# SPGSS2_1.0 register map
Vendor: Texas Instruments
Registers are 32-bit, read-write, no defined reset value unless marked. A register's access mark holds for its fields unless they carry their own. Offsets are as the file gives them; [hi:lo] are bit positions; lines under a group give offsets from that group; {n}, {i} and the like mark numbered series; 'fields as' and 'values as' point back to an identical list; <NAME> marks a mode.

## SPGSS2 (part 3 of 4)
0x27020 SPGSS2_UC3_I2CC_IPSTANDARD_CPU_INT group
  0x00 SPGSS2_UC3_I2CC_IPSTANDARD_IIDX ro — Interrupt index
    [7:0] STAT — I2C Module Interrupt Vector Value. This register provides the highes priority interrupt index. A read clears the corresponding interrupt flag in RIS and MISC. 15h-1Fh = Reserved
      0=NO_INTR (No interrupt pending); 1=RXDONEFG (Data received); 2=TXDONEFG (data transmitted); 3=RXTRG (Receive Trigger); 4=TXTRG (Transmit Trigger); 5=RXFULL (RX FIFO FULL Event/interrupt pending); 6=TXEMPTY (Transmit FIFO/Buffer Empty Event/interrupt pending); 8=NACKFG (Address/Data NACK); 9=STARTFG (Start Event); 10=STOPFG (Stop Event); 11=ARBLOSTFG (Arbitration Lost); 12=PEC_RX_ERR (PEC Receive Error Event); 13=TIMEOUTA (Timeout A Event); 14=TIMEOUTB (Timeout B Event); 16=DMA_DONE_RX (DMA DONE on Channel RX); 17=DMA_DONE_TX (DMA DONE on Channel TX); 19=DMA_PREIRQ_RX (DMA PRE IRQ INTERRUPT); 20=DMA_PREIRQ_TX (DMA PRE IRQ INTERRUPT)
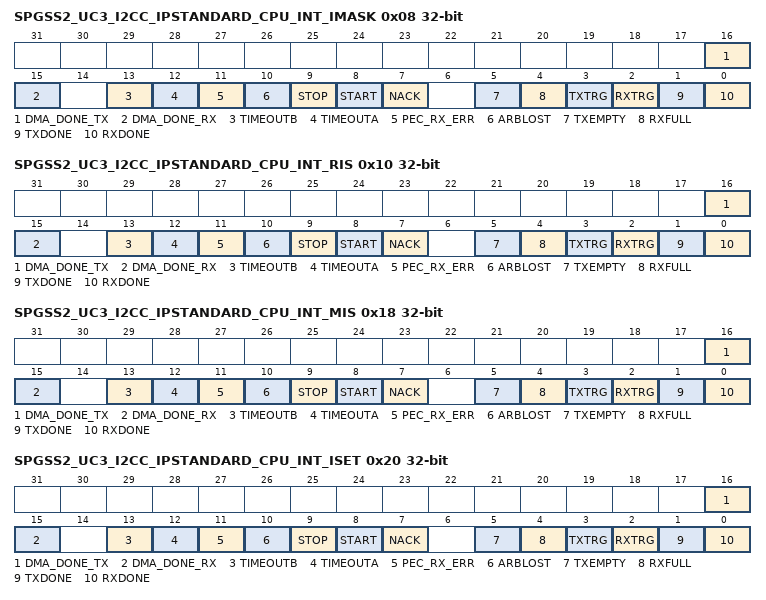
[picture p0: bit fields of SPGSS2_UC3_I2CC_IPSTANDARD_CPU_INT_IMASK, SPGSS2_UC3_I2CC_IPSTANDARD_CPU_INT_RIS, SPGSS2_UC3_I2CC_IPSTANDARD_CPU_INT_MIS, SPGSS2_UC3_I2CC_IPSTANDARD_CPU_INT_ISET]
  0x08 SPGSS2_UC3_I2CC_IPSTANDARD_CPU_INT_IMASK — Interrupt mask
    [16] DMA_DONE_TX — DMA Done on Event Channel TX
      0=CLR (Interrupt disabled); 1=SET (Set Interrupt Mask)
    [15] DMA_DONE_RX — DMA Done on Event Channel RX
      0=CLR (Interrupt disabled); 1=SET (Set Interrupt Mask)
    [13] TIMEOUTB — Timeout B Interrupt
      0=CLR (Clear Interrupt Mask); 1=SET (Set Interrupt Mask)
    [12] TIMEOUTA — TIMEOUTA interrupt
      0=CLR (Clear Interrupt Mask); 1=SET (Set Interrupt Mask)
    [11] PEC_RX_ERR — RX Pec Error Interrupt
      0=CLR (Clear Interrupt Mask); 1=SET (Set Interrupt Mask)
    [10] ARBLOST — Arbitration Lost interrupt
      0=CLR (Clear Interrupt Mask); 1=SET (Set Interrupt Mask)
    [9] STOP — STOP interrupt
      0=CLR (Clear Interrupt Mask); 1=SET (Set Interrupt Mask)
    [8] START — START interrupt
      0=CLR (Clear Interrupt Mask); 1=SET (Set Interrupt Mask)
    [7] NACK — NACK interrupt
      0=CLR (Clear Interrupt Mask); 1=SET (Set Interrupt Mask)
    [5] TXEMPTY — Transmit FIFO/Buffer Empty interrupt.
      0=CLR (Clear Interrupt Mask); 1=SET (Set Interrupt Mask)
    [4] RXFULL — RXFIFO full event
      0=CLR (Clear Interrupt Mask); 1=SET (Set Interrupt Mask)
    [3] TXTRG — Transmit Trigger
      0=CLR (Clear Interrupt Mask); 1=SET (Set Interrupt Mask)
    [2] RXTRG — Receive Trigger
      0=CLR (Clear Interrupt Mask); 1=SET (Set Interrupt Mask)
    [1] TXDONE — Transmit Transaction completed Interrupt
      0=CLR (Clear Interrupt Mask); 1=SET (Set Interrupt Mask)
    [0] RXDONE — RXDONE interrupt
      0=CLR (Clear Interrupt Mask); 1=SET (Set Interrupt Mask)
  0x10 SPGSS2_UC3_I2CC_IPSTANDARD_CPU_INT_RIS — Raw interrupt status
    [16] DMA_DONE_TX — DMA Done on Event Channel TX
      0=CLR (Interrupt disabled); 1=SET (Set Interrupt Mask)
    [15] DMA_DONE_RX — DMA Done on Event Channel RX
      0=CLR (Interrupt disabled); 1=SET (Set Interrupt Mask)
    [13] TIMEOUTB — Timeout B Interrupt
      0=CLR (Interrupt did not occur); 1=SET (Interrupt occured)
    [12] TIMEOUTA — Timeout A Interrupt
      0=CLR (Interrupt did not occur); 1=SET (Set Interrupt Mask)
    [11] PEC_RX_ERR — Receive PEC Error Interrupt: set when the calculated PEC does not match received PEC
      0=CLR (Interrupt did not occur); 1=SET (Interrupt Occured)
    [10] ARBLOST — Arbitration Lost Interrupt: in multi-controller systems, when this controller loses out during arbitration
      0=CLR (Interrupt did not occur); 1=SET (Set Interrupt Mask)
    [9] STOP — STOP Detection Interrupt
      0=CLR (Interrupt did not occur); 1=SET (Set Interrupt Mask)
    [8] START — START Detection Interrupt
      0=CLR (Interrupt did not occur); 1=SET (Set Interrupt Mask)
    [7] NACK — Address/Data NACK Interrupt: set when address or data nack is received
      0=CLR (Interrupt did not occur); 1=SET (Set Interrupt Mask)
    [5] TXEMPTY — Transmit FIFO Empty: set when Transmit FIFO is empty
      0=CLR (Interrupt did not occur); 1=SET (Interrupt occured)
    [4] RXFULL — RXFIFO full event. This interrupt is set when receive FIFO is full.
      0=CLR (Interrupt did not occur); 1=SET (Interrupt occured)
    [3] TXTRG — Transmit Trigger When FIFO is present, as per IFLS settings When FIFO is not present, trigger when transmit buffer is empty
      0=CLR (Clear Interrupt Mask); 1=SET (Set Interrupt Mask)
    [2] RXTRG — Receive Trigger When FIFO is present, as per IFLS settings when FIFO is not present, this indicates when buffer is full
      0=CLR (Clear Interrupt Mask); 1=SET (Set Interrupt Mask)
    [1] TXDONE — Transmit Done Interrupt: TXDONE interrupt is raised when a burst length completes Or, in case of quick command, when a quick command with R/Wn bit set to '0'
      0=CLR (Interrupt did not occur); 1=SET (Set Interrupt Mask)
    [0] RXDONE — Receive Done Interrupt: RXDONE interrupt is raised when a burst length completes Or, in case of quick command, when a quick command with R/Wn bit set to '1'
      0=CLR (Interrupt did not occur); 1=SET (Set Interrupt Mask)
  0x18 SPGSS2_UC3_I2CC_IPSTANDARD_CPU_INT_MIS — Masked interrupt status
    [16] DMA_DONE_TX — DMA Done on Event Channel TX
      0=CLR (Interrupt disabled); 1=SET (Set Interrupt Mask)
    [15] DMA_DONE_RX — DMA Done on Event Channel RX
      0=CLR (Interrupt disabled); 1=SET (Set Interrupt Mask)
    [13] TIMEOUTB — Timeout B Interrupt
      0=CLR (Clear interrupt mask); 1=SET (Set interrupt mask)
    [12] TIMEOUTA — Timeout A Interrupt
      0=CLR (Interrupt did not occur); 1=SET (Set Interrupt Mask)
    [11] PEC_RX_ERR — RX Pec Error Interrupt
      0=CLR (Clear interrupt mask); 1=SET (Set interrupt mask)
    [10] ARBLOST — Arbitration Lost Interrupt
      0=CLR (Interrupt did not occur); 1=SET (Set Interrupt Mask)
    [9] STOP — STOP Detection Interrupt
      0=CLR (Interrupt did not occur); 1=SET (Set Interrupt Mask)
    [8] START — START Detection Interrupt
      0=CLR (Interrupt did not occur); 1=SET (Set Interrupt Mask)
    [7] NACK — Address/Data NACK Interrupt
      0=CLR (Interrupt did not occur); 1=SET (Set Interrupt Mask)
    [5] TXEMPTY — Transmit FIFO Empty masked interrupt. This interrupt is set if all data in the Transmit FIFO have been shifted out and the transmit goes into idle mode.
      0=CLR (Interrupt did not occur); 1=SET (Interrupt occured)
    [4] RXFULL — Masked RXFIFO full event
      0=CLR (Interrupt did not occur); 1=SET (Interrupt occured)
    [3] TXTRG — Transmit Trigger
      0=CLR (Clear Interrupt Mask); 1=SET (Set Interrupt Mask)
    [2] RXTRG — Receive Trigger
      0=CLR (Clear Interrupt Mask); 1=SET (Set Interrupt Mask)
    [1] TXDONE — Transmit Transaction completed Interrupt
      0=CLR (Interrupt did not occur); 1=SET (Set Interrupt Mask)
    [0] RXDONE — Receive Data Interrupt
      0=CLR (Interrupt did not occur); 1=SET (Set Interrupt Mask)
  0x20 SPGSS2_UC3_I2CC_IPSTANDARD_CPU_INT_ISET — Interrupt set
    [16] DMA_DONE_TX — DMA Done on Event Channel TX
      0=NO_EFFECT (Interrupt disabled); 1=SET (Set Interrupt Mask)
    [15] DMA_DONE_RX — DMA Done on Event Channel RX
      0=NO_EFFECT (Interrupt disabled); 1=SET (Set Interrupt Mask)
    [13] TIMEOUTB — Timeout B Interrupt
      0=NO_EFFECT (Writing 0 has no effect); 1=SET (Set interrupt)
    [12] TIMEOUTA — Timeout A interrupt
      0=NO_EFFECT (Writing 0 has no effect); 1=SET (Set Interrupt Mask)
    [11] PEC_RX_ERR — RX Pec Error Interrupt
      0=NO_EFFECT (Writing 0 has no effect); 1=SET (Set interrupt)
    [10] ARBLOST — Arbitration Lost Interrupt
      values as TIMEOUTA
    [9] STOP — STOP Detection Interrupt
      values as TIMEOUTA
    [8] START — START Detection Interrupt
      values as TIMEOUTA
    [7] NACK — Address/Data NACK Interrupt
      values as TIMEOUTA
    [5] TXEMPTY — Transmit FIFO Empty interrupt mask. This interrupt is set if all data in the Transmit FIFO have been shifted out and the transmit goes into idle mode.
      0=NO_EFFECT (Writing 0 has no effect); 1=SET (Set Interrupt)
    [4] RXFULL — RXFIFO full event.
      0=NO_EFFECT (Writing 0 has no effect); 1=SET (Set Interrupt)
    [3] TXTRG — Transmit Trigger
      0=NO_EFFECT (Clear Interrupt Mask); 1=SET (Set Interrupt Mask)
    [2] RXTRG — Receive Trigger
      values as TXTRG
    [1] TXDONE — Transmit Transaction completed Interrupt
      values as TIMEOUTA
    [0] RXDONE — Receive Data Interrupt Signals that a byte has been received
      values as TIMEOUTA
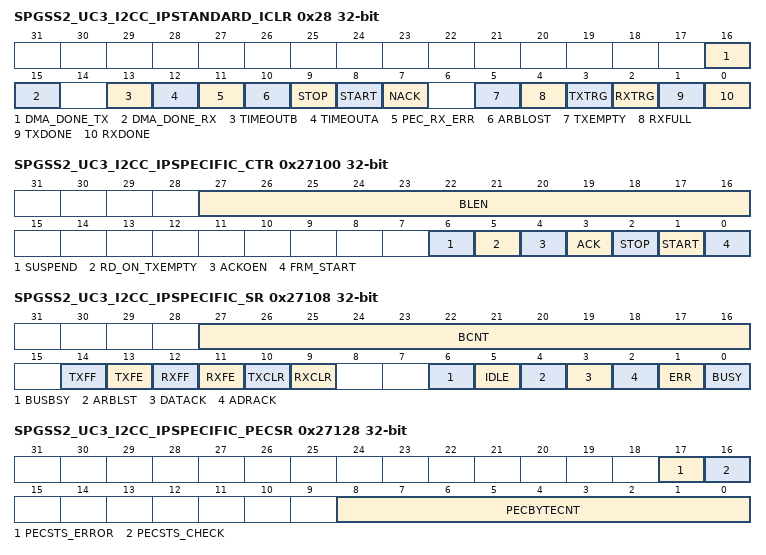
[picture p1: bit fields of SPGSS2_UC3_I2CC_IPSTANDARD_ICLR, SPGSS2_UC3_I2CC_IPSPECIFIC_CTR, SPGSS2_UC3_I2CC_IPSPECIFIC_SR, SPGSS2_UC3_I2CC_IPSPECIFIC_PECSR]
  0x28 SPGSS2_UC3_I2CC_IPSTANDARD_ICLR — Interrupt clear
    [16] DMA_DONE_TX — DMA Done on Event Channel TX
      0=NO_EFFECT (Interrupt disabled); 1=CLR (Set Interrupt Mask)
    [15] DMA_DONE_RX — DMA Done on Event Channel RX
      0=NO_EFFECT (Interrupt disabled); 1=CLR (Set Interrupt Mask)
    [13] TIMEOUTB — Timeout B Interrupt
      0=NO_EFFECT (Writing 0 has no effect); 1=CLR (Clear Interrupt)
    [12] TIMEOUTA — Timeout A interrupt
      0=NO_EFFECT (Writing 0 has no effect); 1=CLR (Set Interrupt Mask)
    [11] PEC_RX_ERR — RX Pec Error Interrupt
      values as TIMEOUTB
    [10] ARBLOST — Arbitration Lost Interrupt
      values as TIMEOUTA
    [9] STOP — STOP Detection Interrupt
      values as TIMEOUTA
    [8] START — START Detection Interrupt
      values as TIMEOUTA
    [7] NACK — Address/Data NACK Interrupt
      values as TIMEOUTA
    [5] TXEMPTY — Transmit FIFO Empty interrupt mask. This interrupt is set if all data in the Transmit FIFO have been shifted out and the transmit goes into idle mode.
      values as TIMEOUTB
    [4] RXFULL — RXFIFO full event.
      values as TIMEOUTB
    [3] TXTRG — Transmit FIFO Trigger
      0=NO_EFFECT (Clear Interrupt Mask); 1=CLR (Set Interrupt Mask)
    [2] RXTRG — Receive Trigger
      values as TXTRG
    [1] TXDONE — Transmit Transaction completed Interrupt
      values as TIMEOUTA
    [0] RXDONE — Receive Data Interrupt Signals that a byte has been received
      values as TIMEOUTA
0x27100 SPGSS2_UC3_I2CC_IPSPECIFIC_CTR — Control Register
  [27:16] BLEN — I2C transaction length This field contains the programmed length of bytes of the Transaction.
    0=MINIMUM (Smallest value); 0xFFF=MAXIMUM (Highest possible value)
  [6] SUSPEND — Suspend external communication
    0=DISABLE (Functional mode resumed); 1=ENABLE (External communication suspended)
  [5] RD_ON_TXEMPTY — Read on TX Empty
    0=DISABLE (No special behavior); 1=ENABLE (When 1 the Controller will transmit all bytes from the TX FIFO before continuing with the programmed Burst Run Read. If the DIR is not set to Read in the MSA then this bit is ignored. The Start must be set in the MCTR for proper I2C protocol. The Controller will first send the Start Condition, I2C Address with R/W bit set to write, before sending the bytes in the TX FIFO. When the TX FIFO is empty, the I2C transaction will continue as programmed in MTCR and MSA without sending a Stop Condition. This is intended to be used to perform simple I2C command based reads transition that will complete after initiating them without having to get an interrupt to turn the bus around.)
  [4] ACKOEN — ACK overrride Enable
    0=DISABLE (No special behavior); 1=ENABLE (When 1 and the Controller is receiving data and the number of bytes indicated in MBLEN have been received, the state machine will generate an rxdone interrupt and wait at the start of the ACK for FW to indicate if an ACK or NACK should be sent. The ACK or NACK is selected by writing the MCTR register and setting ACK accordingly. The other fields in this register can also be written at this time to continue on with the transaction. If a NACK is sent the state machine will automatically send a Stop.)
  [3] ACK — Data Acknowledge Enable. Software needs to configure this bit to send the ACK or NACK. See field decoding in Table: MCTR Field decoding.
    0=DISABLE (The last received data byte of a transaction is not acknowledged automatically .); 1=ENABLE (The last received data byte of a transaction is acknowledged automatically .)
  [2] STOP — Generate STOP
    0=DISABLE (The controller does not generate the STOP condition.); 1=ENABLE (The controller generates the STOP condition. See field decoding in Table: MCTR Field decoding.)
  [1] START — Generate START
    0=DISABLE (The controller does not generate the START condition.); 1=ENABLE (The controller generates the START or repeated START condition. See field decoding in Table: MCTR Field decoding.)
  [0] FRM_START — Start Transfer
    0=DISABLE (In standard mode, this encoding means the Controller is unable to transmit or receive data.); 1=ENABLE (The Controller is able to transmit or receive data. See field decoding in Table: MCTR Field decoding.)
0x27108 SPGSS2_UC3_I2CC_IPSPECIFIC_SR ro — Status Register
  [27:16] BCNT — Transaction Count This field contains the current count-down value of the transaction.
    values as SPGSS2_UC3_I2CC_IPSPECIFIC_CTR.BLEN
  [14] TXFF — Transmit FIFO Full The meaning of this bit depends on the state of the FEN bit in the CTL0 register.
    0=CLEARED (The transmitter is not full.); 1=SET (If the FIFO is disabled (FEN is 0), the transmit holding register is full. If the FIFO is enabled (FEN is 1), the transmit FIFO is full.)
  [13] TXFE — Transmit FIFO Empty The meaning of this bit depends on the state of the FEN bit in the CTL0 register.
    0=CLEARED (The transmitter has data to transmit.); 1=SET (If the FIFO is disabled (FEN is 0), the transmit holding register is empty. If the FIFO is enabled (FEN is 1), the transmit FIFO is empty.)
  [12] RXFF — Receive FIFO Full The meaning of this bit depends on the state of the FEN bit in the CTL0 register.
    0=CLEARED (The receiver can receive data.); 1=SET (If the FIFO is disabled (FEN is 0), the receive holding register is full. If the FIFO is enabled (FEN is 1), the receive FIFO is full.)
  [11] RXFE — Receive FIFO Empty The meaning of this bit depends on the state of the FEN bit in the CTL0 register.
    0=CLEARED (The receiver is not empty.); 1=SET (If the FIFO is disabled (FEN is 0), the receive holding register is empty. If the FIFO is enabled (FEN is 1), the receive FIFO is empty.)
  [10] TXCLR — TX FIFO Clear Status
    0=CLEARED (FIFO is not cleared); 1=SET (FIFO clear is complete)
  [9] RXCLR — RX FIFO Clear Status
    values as TXCLR
  [6] BUSBSY — I2C Bus is Busy Controller State Machine will wait until this bit to be cleared before starting a transaction. When first enabling the Controller in multi Controller environments, FW should wait for one I2C clock period after setting ACTIVE high before writing to the CTR register to start the transaction so that if SCL goes low it will trigger the BUSBSY.
    0=CLEARED (The I2C bus is idle.); 1=SET ('This Status bit is set on a START or when SCL goes low. It is cleared on a STOP, or when a SCL high bus busy timeout occurs and SCL and SDA are both high. This status is cleared when the ACTIVE bit is low. Note that the Controller State Machine will wait until this bit is cleared before starting an I2C transaction. When first enabling the Controller in multi Controller environments, FW should wait for one I2C clock period after setting ACTIVE high before writing to the MTCR register to start the transaction so that if SCL goes low it will trigger the BUSBSY.)
  [5] IDLE — I2C Idle
    0=CLEARED (The I2C controller is not idle.); 1=SET (The I2C controller is idle.)
  [4] ARBLST — Arbitration Lost
    0=CLEARED (The I2C controller won arbitration.); 1=SET (The I2C controller lost arbitration.)
  [3] DATACK — Acknowledge Data
    0=CLEARED (The transmitted data was acknowledged); 1=SET (The transmitted data was not acknowledged.)
  [2] ADRACK — Acknowledge Address
    0=CLEARED (The transmitted address was acknowledged); 1=SET (The transmitted address was not acknowledged.)
  [1] ERR — Error The error can be from the Target address not being acknowledged or the transmit data not being acknowledged.
    0=CLEARED (No error was detected on the last operation.); 1=SET (An error occurred on the last operation.)
  [0] BUSY — FSM Busy The BUSY bit is set during an ongoing transaction, so is set during the transmit/receive of the amount of data set in MBLEN including START, RESTART, Address and STOP signal generation when required for the current transaction.
    0=CLEARED (The controller is idle.); 1=SET (The controller is busy.)
0x27118 SPGSS2_UC3_I2CC_IPSPECIFIC_GFCTL — I2C Glitch Filter Control
  [8] AGFEN — Analog Glitch Suppression Enable
    0=DISABLE (Analog Glitch Filter disable); 1=ENABLE (Analog Glitch Filter enable)
0x27128 SPGSS2_UC3_I2CC_IPSPECIFIC_PECSR — PEC status register
  [17] PECSTS_ERROR — This status bit indicates if a PEC check error occurred in the transaction that occurred before the last Stop. Latched on Stop.
    0=CLEARED (Indicates PEC check error did not occurr in the transaction that occurred before the last Stop); 1=SET (Indicates if a PEC check error occurred in the transaction that occurred before the last Stop)
  [16] PECSTS_CHECK — This status bit indicates if the PEC was checked in the transaction that occurred before the last Stop. Latched on Stop.
    0=CLEARED (Indicates PEC was not checked in the transaction that occurred before the last Stop); 1=SET (Indicates if the PEC was checked in the transaction that occurred before the last Stop)
  [8:0] PECBYTECNT — PEC Byte Count This is the current PEC Byte Count of the Controller State Machine.
    0=MINIMUM (Minimum Value); 0x1FF=MAXIMUM (Maximum Value)
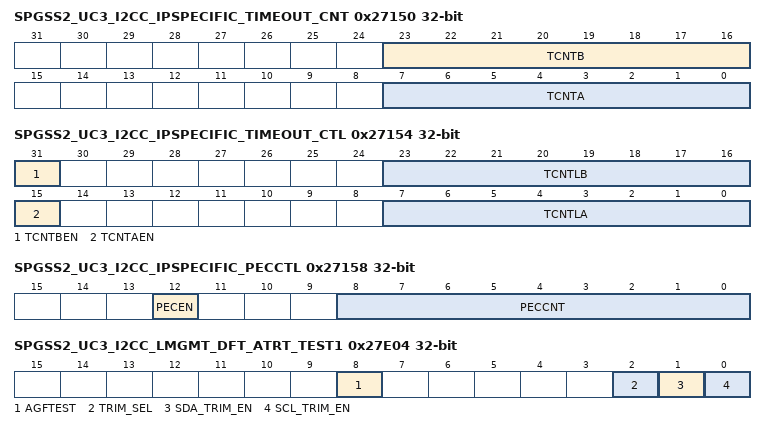
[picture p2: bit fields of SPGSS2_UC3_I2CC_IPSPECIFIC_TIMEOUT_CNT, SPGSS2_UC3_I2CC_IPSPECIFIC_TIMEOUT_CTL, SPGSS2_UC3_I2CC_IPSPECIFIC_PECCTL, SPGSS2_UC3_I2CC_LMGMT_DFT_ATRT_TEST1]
0x27150 SPGSS2_UC3_I2CC_IPSPECIFIC_TIMEOUT_CNT access per field — I2C Timeout Count Register
  [23:16] TCNTB rw — Timeout Count B Current Count: This field contains the upper 8 bits of a 12-bit current counter for timeout counter B
    0=MINIMUM (Smallest Value); 255=MAXIMUM (Highest possible value)
  [7:0] TCNTA ro — Timeout Count A Current Count: This field contains the upper 8 bits of a 12-bit current counter for timeout counter A
    values as TCNTB
0x27154 SPGSS2_UC3_I2CC_IPSPECIFIC_TIMEOUT_CTL — I2C Timeout Count Control Register
  [31] TCNTBEN — Timeout Counter B Enable
    0=DISABLE (Disable Timeout Counter B); 1=ENABLE (Enable Timeout Counter B)
  [23:16] TCNTLB — Timeout Count B Load: Counter B is used for SCL High Detection. This field contains the upper 8 bits of a 12-bit pre-load value for the Timeout B count. NOTE: The value of CNTLB must be greater than 1h. Each count is equal to 1* clock period. For example, with 10MHz functional clock one timeout period will be equal to1*100ns.
    0=MINIMUM (Smallest possible value); 255=MAXIMUM (Highest possible value)
  [15] TCNTAEN — Timeout Counter A Enable
    values as TCNTBEN
  [7:0] TCNTLA — Timeout counter A load value Counter A is used for SCL low detection. This field contains the upper 8 bits of a 12-bit pre-load value for the Timeout A count. NOTE: The value of CNTLA must be greater than 1h. Each count is equal to 520 times the timeout period of functional clock. For example, with 8MHz functional clock and a 100KHz operating I2C clock, one timeout period will be equal to (1 / 8MHz) * 520 or 65 us.
    values as SPGSS2_UC3_I2CC_IPSPECIFIC_TIMEOUT_CNT.TCNTB
0x27158 SPGSS2_UC3_I2CC_IPSPECIFIC_PECCTL — I2C PEC control register
  [12] PECEN — PEC Enable This bit enables the SMB Packet Error Checking (PEC). When enabled the PEC is calculated on all bits except the Start, Stop, Ack and Nack. The PEC LSFR and the Byte Counter is set to 0 when the State Machine is in the IDLE state, which occur following a Stop or when a timeout occurs. The Counter is also set to 0 after the PEC byte is sent or received. Note that the NACK is automatically send following a PEC byte that results in a PEC error. The PEC Polynomial is x^8 + x^2 + x^1 + 1.
    0=DISABLE (PEC is disabled); 1=ENABLE (PEC is enabled)
  [8:0] PECCNT — PEC Count When this field is non zero, the number of I2C bytes are counted (Note that although the PEC is calculated on the I2C address it is not counted at a byte). When the byte count = PECCNT and the state machine is transmitting, the contents of the LSFR is loaded into the shift register instead of the byte received from the Tx FIFO. When the state machine is receiving, after the last bit of this byte is received the LSFR is checked and if it is non-zero, a PEC RX Error interrupt is generated. The I2C packet must be padded to include the PEC byte for both transmit and receive. In transmit mode the FIFO must be loaded with a dummy PEC byte. In receive mode the PEC byte will be passed to the Rx FIFO. In the normal Controller use case, FW would set PECEN=1 and PECCNT=SMB packet length (Not including Target Address byte, but including the PEC byte). FW would then configure DMA to allow the packet to complete unassisted and write MCTR to initiate the transaction. Note that when the byte count = PEC CNT, the byte count is reset to 0 and multiple PEC calculation can automatically occur within a single I2C transaction. Note that any write to the I2PECCTL Register will clear the current PEC Byte Count in the State Machine.
    0=MINIMUM (Minimum Value); 0x1FF=MAXIMUM (Maximum Value)
0x27E04 SPGSS2_UC3_I2CC_LMGMT_DFT_ATRT_TEST1 — Test 0 register
  [8] AGFTEST
  [2] TRIM_SEL — Select for which branch to trim
    0=FALLING_EDGE (Select Trim on falling edge); 1=RISING_EDGE (Select Trim on rising edge)
  [1] SDA_TRIM_EN — Analog glitch filter trimming enable for SDA
    0=DISABLE (Disable Trim for SDA); 1=ENABLE (Enable Trim for SDA)
  [0] SCL_TRIM_EN — Analog glitch filter trimming enable for SCL
    0=DISABLE (Disable Trim for SCL); 1=ENABLE (Enable Trim for SCL)
{0x41000+0x2000*i} SPGSS2_UC{i}_I2CT_IPSTANDARD_CLKDIV (i=0..3) — Clock Divider
  [2:0] RATIO — Selects divide ratio of module clock Division factor 0 : DIV_BY_1 1 : DIV_BY_2 .... 63: DIV_BY_64
{0x41008+0x2000*i} SPGSS2_UC{i}_I2CT_IPSTANDARD_CLKSEL (i=0..3) — Clock Select for Ultra Low Power peripherals
  [3] BUSCLK_SEL — Selects BUS CLK as clock source if enabled
    0=DISABLE (Does not select this clock as a source); 1=ENABLE (Select this clock as a source)
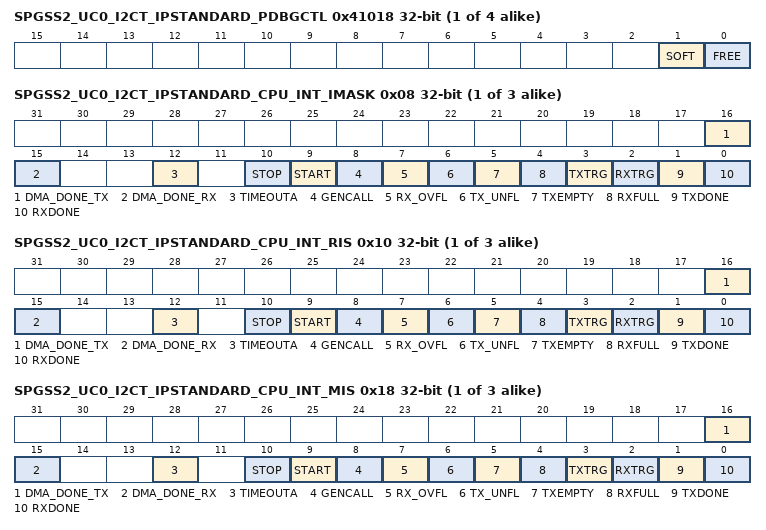
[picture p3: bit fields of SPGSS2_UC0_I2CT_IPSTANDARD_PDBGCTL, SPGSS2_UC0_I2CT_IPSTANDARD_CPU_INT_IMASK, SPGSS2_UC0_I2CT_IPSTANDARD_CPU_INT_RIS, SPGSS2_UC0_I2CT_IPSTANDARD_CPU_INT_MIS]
{0x41018+0x2000*i} SPGSS2_UC{i}_I2CT_IPSTANDARD_PDBGCTL (i=0..3) — Peripheral Debug Control
  [1] SOFT — Soft halt boundary control. This function is only available, if [FREE] is set to 'STOP'
    0=DEPRECATED (Not supported); 1=DELAYED (The peripheral blocks the debug freeze until it has reached a boundary where it can resume without corruption)
  [0] FREE — Free run control
    0=STOP (The peripheral freezes functionality while the Core Halted input is asserted and resumes when it is deasserted.); 1=RUN (The peripheral ignores the state of the Core Halted input)
{0x41020+0x2000*i} SPGSS2_UC{i}_I2CT_IPSTANDARD_CPU_INT group (i=0..2)
  0x00 SPGSS2_UC{i}_I2CT_IPSTANDARD_IIDX ro — Interrupt index
    [7:0] STAT — I2C Module Interrupt Vector Value. This register provides the highes priority interrupt index. A read clears the corresponding interrupt flag in RIS and MISC. 15h-1Fh = Reserved
      0=NO_INTR (No interrupt pending); 1=RXDONEFG (Receive Done Flag); 2=TXDONEFG (Transmit Done Flag); 3=RXTRG (receive FIFO Trigger Level); 4=TXTRG (transmit FIFO Trigger level); 5=RXFULL (RX FIFO FULL Event/interrupt pending); 6=TXEMPTY (Transmit FIFO/Buffer Empty Event/interrupt pending); 7=TX_UNFL (Target TX FIFO underflow); 8=RX_OVFL (Target RX FIFO overflow event); 9=GENCALL (General Call Event); 10=STARTFG (Start Event); 11=STOPFG (Stop Event); 12=PEC_RX_ERR (PEC receive error event); 13=TIMEOUTA (Timeout A Event); 14=TIMEOUTB (Timeout B Event); 16=DMA_DONE_RX (DMA DONE on Channel RX); 17=DMA_DONE_TX (DMA DONE on Channel TX); 18=ARBLOSTFG (Arbitration Lost); 19=DMA_PREIRQ_RX (DMA PRE IRQ INTERRUPT); 20=DMA_PREIRQ_TX (DMA PRE IRQ INTERRUPT)
  0x08 SPGSS2_UC{i}_I2CT_IPSTANDARD_CPU_INT_IMASK — Interrupt mask
    [all] fields
      0=CLR (Clear Interrupt Mask); 1=SET (Set Interrupt Mask)
    [16] DMA_DONE_TX — DMA Done on Event Channel TX
    [15] DMA_DONE_RX — DMA Done on Event Channel RX
    [12] TIMEOUTA — Timeout A Interrupt
    [10] STOP — Stop Condition Interrupt
    [9] START — Start Condition Interrupt
    [8] GENCALL — General Call Interrupt
    [7] RX_OVFL — Target RX FIFO overflow
    [6] TX_UNFL — Target TX FIFO underflow
    [5] TXEMPTY — Target Transmit FIFO Empty interrupt mask. This interrupt is set if all data in the Transmit FIFO have been shifted out and the transmit goes into idle mode.
    [4] RXFULL — RXFIFO full event. This interrupt is set if an Target RX FIFO is full.
    [3] TXTRG — Transmit Trigger
    [2] RXTRG — Receive Trigger
    [1] TXDONE — Transmit Transaction completed Interrupt
    [0] RXDONE — Receive Data Interrupt Signals that a byte has been received
  0x10 SPGSS2_UC{i}_I2CT_IPSTANDARD_CPU_INT_RIS — Raw interrupt status
    [16] DMA_DONE_TX — DMA Done on Event Channel TX
      0=CLR (Clear interrupt); 1=SET (Set interrupt)
    [15] DMA_DONE_RX — DMA Done on Event Channel RX
      0=CLR (Clear interrupt); 1=SET (Set interrupt)
    [12] TIMEOUTA — Timeout A Interrupt
      0=CLR (Interrupt did not occur); 1=SET (Set Interrupt Mask)
    [10] STOP — Stop Condition Interrupt: set on a STOP condition if this target was being addressed
      0=CLR (Clear Interrupt); 1=SET (Interrupt is set when target is addressed and STOP condition is received)
    [9] START — Start Condition Interrupt: is set after a START condition is received and this target is addressed
      0=CLR (Clear interrupt); 1=SET (Set when a START condition is receivied and address matches target's address)
    [8] GENCALL — General Call Interrupt: set when a general call is received
      0=CLR (Clear Interrupt Mask); 1=SET (Set Interrupt Mask)
    [7] RX_OVFL — Receive FIFO overflow
      0=CLR (Interrupt did not occur); 1=SET (Interrupt Occured)
    [6] TX_UNFL — Transmit FIFO underflow
      0=CLR (Interrupt did not occur); 1=SET (Interrupt occured)
    [5] TXEMPTY — Transmit FIFO Empty Interrupt. This interrupt is set if all data in the Transmit FIFO have been shifted out and FSM goes into idle mode.
      0=CLR (Interrupt did not occur); 1=SET (Interrupt occured)
    [4] RXFULL — RXFIFO full event. This interrupt is set if an RX FIFO is full.
      0=CLR (Clear Interrupt Mask); 1=SET (Interrupt occured)
    [3] TXTRG — Transmit Trigger When FIFO is present, triggered as per IFLS settings When FIFO is not present, trigger when transmit buffer is empty
      0=CLR (Clear Interrupt Mask); 1=SET (Set Interrupt Mask)
    [2] RXTRG — Receive Trigger When FIFO is present, triggered as per IFLS settings when FIFO is not present, this indicates when buffer is full
      0=CLR (Clear Interrupt Mask); 1=SET (Set Interrupt Mask)
    [1] TXDONE — Transmission Done Interrupt: Set after a byte is transmitted
      0=CLR (Interrupt did not occur); 1=SET (Set Interrupt Mask)
    [0] RXDONE — Receive Done Interrupt: Set after a byte is received
      0=CLR (Interrupt did not occur); 1=SET (Set Interrupt Mask)
  0x18 SPGSS2_UC{i}_I2CT_IPSTANDARD_CPU_INT_MIS — Masked interrupt status
    [16] DMA_DONE_TX — DMA Done on Event Channel TX
      0=CLR (Clear MIS); 1=SET (Set MIS)
    [15] DMA_DONE_RX — DMA Done on Event Channel RX
      0=CLR (Clear MIS); 1=SET (Set MIS)
    [12] TIMEOUTA — Timeout A Interrupt
      0=CLR (Interrupt did not occur); 1=SET (Set Interrupt Mask)
    [10] STOP — STOP Detection Interrupt
      0=CLR (Clear MIS); 1=SET (Set MIS)
    [9] START — START Detection Interrupt
      0=CLR (Clear MIS); 1=SET (Set MIS)
    [8] GENCALL — General Call Interrupt
      0=CLR (Interrupt did not occur); 1=SET (Set Interrupt Mask)
    [7] RX_OVFL — Target RX FIFO overflow
      0=CLR (Clear interrupt mask); 1=SET (Set interrupt mask)
    [6] TX_UNFL — Target TX FIFO underflow
      0=CLR (Clear interrupt mask); 1=SET (Set interrupt mask)
    [5] TXEMPTY — Transmit FIFO Empty interrupt mask. This interrupt is set if all data in the Transmit FIFO have been shifted out and the transmit goes into idle mode.
      0=CLR (Interrupt did not occur); 1=SET (Interrupt occured)
    [4] RXFULL — RXFIFO full event. This interrupt is set if an RX FIFO is full.
      0=CLR (Clear Interrupt Mask); 1=SET (Interrupt occured)
    [3] TXTRG — Transmit Trigger
      0=CLR (Clear Interrupt Mask); 1=SET (Set Interrupt Mask)
    [2] RXTRG — Receive Trigger
      0=CLR (Clear Interrupt Mask); 1=SET (Set Interrupt Mask)
    [1] TXDONE — Transmit Transaction completed Interrupt
      0=CLR (Interrupt did not occur); 1=SET (Set Interrupt Mask)
    [0] RXDONE — Receive Data Interrupt Signals that a byte has been received
      0=CLR (Interrupt did not occur); 1=SET (Set Interrupt Mask)
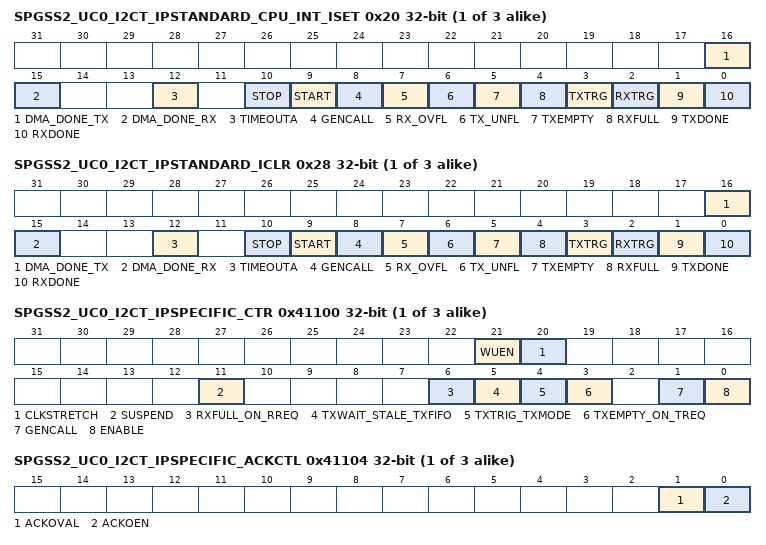
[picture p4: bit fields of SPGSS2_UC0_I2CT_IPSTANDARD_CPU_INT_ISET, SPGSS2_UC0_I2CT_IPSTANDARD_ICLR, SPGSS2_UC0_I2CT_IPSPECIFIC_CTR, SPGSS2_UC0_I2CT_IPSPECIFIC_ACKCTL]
  0x20 SPGSS2_UC{i}_I2CT_IPSTANDARD_CPU_INT_ISET — Interrupt set
    [16] DMA_DONE_TX — DMA Done on Event Channel TX
      0=NO_EFFECT (Writing 0 has no effect); 1=SET (Set interrupt)
    [15] DMA_DONE_RX — DMA Done on Event Channel RX
      0=NO_EFFECT (Writing 0 has no effect); 1=SET (Set interrupt)
    [12] TIMEOUTA — Timeout A interrupt
      values as SPGSS2_UC3_I2CC_IPSTANDARD_CPU_INT.SPGSS2_UC3_I2CC_IPSTANDARD_CPU_INT_ISET.TIMEOUTA
    [10] STOP — Stop Condition Interrupt
      0=NO_EFFECT (Writing 0 has no effect); 1=SET (Set interrupt)
    [9] START — Start Condition Interrupt
      0=NO_EFFECT (Writing 0 has no effect); 1=SET (Set interrupt)
    [8] GENCALL — General Call Interrupt
      values as SPGSS2_UC3_I2CC_IPSTANDARD_CPU_INT.SPGSS2_UC3_I2CC_IPSTANDARD_CPU_INT_ISET.TIMEOUTA
    [7] RX_OVFL — Target RX FIFO overflow
      0=NO_EFFECT (Writing 0 has no effect); 1=SET (Set interrupt)
    [6] TX_UNFL — Target TX FIFO underflow
      0=NO_EFFECT (Writing 0 has no effect); 1=SET (Set interrupt)
    [5] TXEMPTY — Transmit FIFO Empty interrupt mask. This interrupt is set if all data in the Transmit FIFO have been shifted out and the transmit goes into idle mode.
      0=NO_EFFECT (Writing 0 has no effect); 1=SET (Set Interrupt)
    [4] RXFULL — RXFIFO full event. This interrupt is set if an RX FIFO is full.
      0=NO_EFFECT (Clear Interrupt Mask); 1=SET (Set Interrupt)
    [3] TXTRG — Transmit Trigger
      values as SPGSS2_UC3_I2CC_IPSTANDARD_CPU_INT.SPGSS2_UC3_I2CC_IPSTANDARD_CPU_INT_ISET.TXTRG
    [2] RXTRG — Receive Trigger
      values as SPGSS2_UC3_I2CC_IPSTANDARD_CPU_INT.SPGSS2_UC3_I2CC_IPSTANDARD_CPU_INT_ISET.TXTRG
    [1] TXDONE — Target Transmit Transaction completed Interrupt
      values as SPGSS2_UC3_I2CC_IPSTANDARD_CPU_INT.SPGSS2_UC3_I2CC_IPSTANDARD_CPU_INT_ISET.TIMEOUTA
    [0] RXDONE — Target Receive Data Interrupt Signals that a byte has been received
      values as SPGSS2_UC3_I2CC_IPSTANDARD_CPU_INT.SPGSS2_UC3_I2CC_IPSTANDARD_CPU_INT_ISET.TIMEOUTA
  0x28 SPGSS2_UC{i}_I2CT_IPSTANDARD_ICLR — Interrupt clear
    [16] DMA_DONE_TX — DMA Done on Event Channel TX
      0=NO_EFFECT (Writing 0 has no effect); 1=CLR (Clear interrupt)
    [15] DMA_DONE_RX — DMA Done on Event Channel RX
      values as DMA_DONE_TX
    [12] TIMEOUTA — Timeout A interrupt
      values as SPGSS2_UC3_I2CC_IPSTANDARD_CPU_INT.SPGSS2_UC3_I2CC_IPSTANDARD_ICLR.TIMEOUTA
    [10] STOP — Target STOP Detection Interrupt
      values as DMA_DONE_TX
    [9] START — Target START Detection Interrupt
      values as DMA_DONE_TX
    [8] GENCALL — General Call Interrupt
      values as SPGSS2_UC3_I2CC_IPSTANDARD_CPU_INT.SPGSS2_UC3_I2CC_IPSTANDARD_ICLR.TIMEOUTA
    [7] RX_OVFL — Target RX FIFO overflow
      values as SPGSS2_UC3_I2CC_IPSTANDARD_CPU_INT.SPGSS2_UC3_I2CC_IPSTANDARD_ICLR.TIMEOUTB
    [6] TX_UNFL — Target TX FIFO underflow
      values as SPGSS2_UC3_I2CC_IPSTANDARD_CPU_INT.SPGSS2_UC3_I2CC_IPSTANDARD_ICLR.TIMEOUTB
    [5] TXEMPTY — Transmit FIFO Empty interrupt mask. This interrupt is set if all data in the Transmit FIFO have been shifted out and the transmit goes into idle mode.
      values as SPGSS2_UC3_I2CC_IPSTANDARD_CPU_INT.SPGSS2_UC3_I2CC_IPSTANDARD_ICLR.TIMEOUTB
    [4] RXFULL — RXFIFO full event. This interrupt is set if an RX FIFO is full.
      0=NO_EFFECT (Clear Interrupt Mask); 1=CLR (Clear Interrupt)
    [3] TXTRG — Transmit Trigger
      values as SPGSS2_UC3_I2CC_IPSTANDARD_CPU_INT.SPGSS2_UC3_I2CC_IPSTANDARD_ICLR.TXTRG
    [2] RXTRG — Receive Trigger
      values as SPGSS2_UC3_I2CC_IPSTANDARD_CPU_INT.SPGSS2_UC3_I2CC_IPSTANDARD_ICLR.TXTRG
    [1] TXDONE — Target Transmit Transaction completed Interrupt
      values as SPGSS2_UC3_I2CC_IPSTANDARD_CPU_INT.SPGSS2_UC3_I2CC_IPSTANDARD_ICLR.TIMEOUTA
    [0] RXDONE — Target Receive Data Interrupt Signals that a byte has been received
      values as SPGSS2_UC3_I2CC_IPSTANDARD_CPU_INT.SPGSS2_UC3_I2CC_IPSTANDARD_ICLR.TIMEOUTA
{0x41050+0x2000*i} SPGSS2_UC{i}_I2CT_IPSTANDARD_DMA_TRIG1 group (i=0..3)
  0x08 SPGSS2_UC{i}_I2CT_IPSTANDARD_DMA_TRIG1_IMASK — Interrupt mask
    [2] RXTRG — Receive Trigger
      0=CLR (Clear Interrupt Mask); 1=SET (Set Interrupt Mask)
  0x10 SPGSS2_UC{i}_I2CT_IPSTANDARD_DMA_TRIG1_RIS — Raw interrupt status
    fields as SPGSS2_UC0_I2CT_IPSTANDARD_DMA_TRIG1.SPGSS2_UC{i}_I2CT_IPSTANDARD_DMA_TRIG1_IMASK
  0x18 SPGSS2_UC{i}_I2CT_IPSTANDARD_DMA_TRIG1_MIS — Masked interrupt status
    fields as SPGSS2_UC0_I2CT_IPSTANDARD_DMA_TRIG1.SPGSS2_UC{i}_I2CT_IPSTANDARD_DMA_TRIG1_IMASK
  0x20 SPGSS2_UC{i}_I2CT_IPSTANDARD_DMA_TRIG1_ISET — Interrupt set
    [2] RXTRG — Receive Trigger
      values as SPGSS2_UC3_I2CC_IPSTANDARD_CPU_INT.SPGSS2_UC3_I2CC_IPSTANDARD_CPU_INT_ISET.TXTRG
{0x41080+0x2000*i} SPGSS2_UC{i}_I2CT_IPSTANDARD_DMA_TRIG0 group (i=0..3)
  0x08 SPGSS2_UC{i}_I2CT_IPSTANDARD_DMA_TRIG0_IMASK — Interrupt mask
    [3] TXTRG — Transmit Trigger
      0=CLR (Clear Interrupt Mask); 1=SET (Set Interrupt Mask)
  0x10 SPGSS2_UC{i}_I2CT_IPSTANDARD_DMA_TRIG0_RIS — Raw interrupt status
    fields as SPGSS2_UC0_I2CT_IPSTANDARD_DMA_TRIG0.SPGSS2_UC{i}_I2CT_IPSTANDARD_DMA_TRIG0_IMASK
  0x18 SPGSS2_UC{i}_I2CT_IPSTANDARD_DMA_TRIG0_MIS — Masked interrupt status
    fields as SPGSS2_UC0_I2CT_IPSTANDARD_DMA_TRIG0.SPGSS2_UC{i}_I2CT_IPSTANDARD_DMA_TRIG0_IMASK
  0x20 SPGSS2_UC{i}_I2CT_IPSTANDARD_DMA_TRIG0_ISET — Interrupt set
    [3] TXTRG — Transmit Trigger
      values as SPGSS2_UC3_I2CC_IPSTANDARD_CPU_INT.SPGSS2_UC3_I2CC_IPSTANDARD_CPU_INT_ISET.TXTRG
{0x410E4+0x2000*i} SPGSS2_UC{i}_I2CT_IPSTANDARD_INTCTL (i=0..3) — Interrupt control register
  [0] INTEVAL — Writing a 1 to this field re-evaluates the interrupt sources.
    0=DISABLE (The interrupt or event line is disabled.); 1=EVAL (The interrupt or event line is in software mode. Software must clear the RIS.)
{0x41100+0x2000*i} SPGSS2_UC{i}_I2CT_IPSPECIFIC_CTR (i=0..2) — I2C Target Control Register
  [21] WUEN — Target Wakeup Enable
    0=DISABLE (When 0, the Target is not allowed to clock stretch on START detection); 1=ENABLE (When 1, the Target is allowed to clock stretch on START detection and wait for faster clock to be abvailable. This allows clean wake up support for I2C in low power mode use cases)
  [20] CLKSTRETCH — Clock Stretch Enable
    0=DISABLE (clock stretching is disabled); 1=ENABLE (clock stretching is enabled)
  [11] SUSPEND — Suspend external communication
    values as SPGSS2_UC3_I2CC_IPSPECIFIC_CTR.SUSPEND
  [6] RXFULL_ON_RREQ — Rx full interrupt generated on RREQ condition as indicated in SSR
    0=DISABLE (When 0, RIS:SRXFULL will be set when only the Target RX FIFO is full. This allows the SRXFULL interrupt to be used to indicate that the I2C bus is being clock stretched and that the FW must either read the RX FIFO or ACK/NACK the current Rx byte.); 1=ENABLE (When 1, RIS:SRXFULL will be set when the Target State Machine is in the RX_WAIT or RX_ACK_WAIT states which occurs when the I2C transaction is clock stretched because the RX FIFO is full or the ACKOEN has been set and the state machine is waiting for FW to ACK/NACK the current byte.)
  [5] TXWAIT_STALE_TXFIFO — Tx transfer waits when stale data in Tx FIFO. This prevents stale bytes left in the TX FIFO from automatically being sent on the next I2C packet. Note: this should be used with TXEMPTY_ON_TREQ set to prevent the Target State Machine from waiting for TX FIFO data without an interrupt notification when the FIFO data is stale.
    0=DISABLE (When 0, the TX FIFO empty signal to the Target State Machine indicates that the TX FIFO is empty.); 1=ENABLE (When 1, the TX FIFO empty signal to the Target State Machine will indicate that the TX FIFO is empty or that the TX FIFO data is stale. The TX FIFO data is determined to be stale when there is data in the TX FIFO when the Target State Machine leaves the TXMODE as defined in the SSR register. This can occur is a Stop or timeout occur when there are bytes left in the TX FIFO.)
  [4] TXTRIG_TXMODE — Tx Trigger when Target FSM is in Tx Mode
    0=DISABLE (No special behavior); 1=ENABLE (When 1, RIS:TXTRG will be set when the Target TX FIFO has reached the trigger level AND the Target State Machine is in the TXMODE as defined in the SSR register. When cleared RIS:TXTRG will be set when the Target TX FIFO is at or above the trigger level. This setting can be used to hold off the TX DMA until a transaction starts. This allows the DMA to be configured when the I2C is idle but have it wait till the transaction starts to load the Target TX FIFO, so it can load from a memory buffer that might be changing over time.)
  [3] TXEMPTY_ON_TREQ — Tx Empty Interrupt on TREQ
    0=DISABLE (When 0, RIS:TXEMPTY will be set when only the Target TX FIFO is empty. This allows the TXEMPTY interrupt to be used to indicate that the I2C bus is being clock stretched and that Target TX data is required.); 1=ENABLE (When 1, RIS:TXEMPTY will be set when the Target State Machine is in the TX_WAIT state which occurs when the TX FIFO is empty AND the I2C transaction is clock stretched waiting for the FIFO to receive data.)
  [1] GENCALL — General call response enable Modify only when UCSWRST = 1. 0b = Do not respond to a general call 1b = Respond to a general call
    0=DISABLE (Do not respond to a general call); 1=ENABLE (Respond to a general call)
  [0] ENABLE — Setting this bit enables the module.
    0=DISABLE (Disables module operation.); 1=ENABLE (Enables module operation.)
{0x41104+0x2000*i} SPGSS2_UC{i}_I2CT_IPSPECIFIC_ACKCTL (i=0..2) — I2C Target ACK Control
  [1] ACKOVAL — ACK Override Value Note: Override control is not applicable to Address frame. Bytes following address frame can be acknowledged using ACKOVAL.
    0=DISABLE (An ACK is sent indicating valid data or command.); 1=ENABLE (A NACK is sent indicating invalid data or command.)
  [0] ACKOEN — I2C Target ACK Override Enable Read SR.ACKOEN to check current status of this bit
    0=DISABLE (A response in not provided.); 1=ENABLE (An ACK or NACK is sent according to the value written to the ACKOVAL bit.)
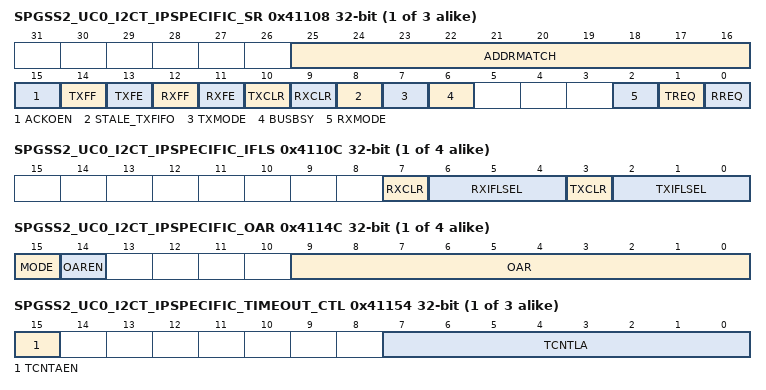
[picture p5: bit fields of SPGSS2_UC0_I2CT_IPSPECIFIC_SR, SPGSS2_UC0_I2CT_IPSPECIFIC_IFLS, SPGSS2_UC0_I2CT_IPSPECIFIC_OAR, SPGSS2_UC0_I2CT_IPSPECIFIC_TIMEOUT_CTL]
{0x41108+0x2000*i} SPGSS2_UC{i}_I2CT_IPSPECIFIC_SR access per field (i=0..2) — Status Register
  [25:16] ADDRMATCH rw — Indicates the address for which Target address match happened
    0=MINIMUM (Minimum Value); 0x3FF=MAXIMUM (Maximum Value)
  [15] ACKOEN ro — Status of ACK Override Enable
    0=DISABLE (ACK override is disabled); 1=ENABLE (ACK override was enabled in design)
  [14] TXFF ro — Transmit FIFO Full The meaning of this bit depends on the state of the FEN bit in the CTL0 register.
    values as SPGSS2_UC3_I2CC_IPSPECIFIC_SR.TXFF
  [13] TXFE ro — Transmit FIFO Empty The meaning of this bit depends on the state of the FEN bit in the CTL0 register.
    values as SPGSS2_UC3_I2CC_IPSPECIFIC_SR.TXFE
  [12] RXFF ro — Receive FIFO Full The meaning of this bit depends on the state of the FEN bit in the CTL0 register.
    values as SPGSS2_UC3_I2CC_IPSPECIFIC_SR.RXFF
  [11] RXFE ro — Receive FIFO Empty The meaning of this bit depends on the state of the FEN bit in the CTL0 register.
    values as SPGSS2_UC3_I2CC_IPSPECIFIC_SR.RXFE
  [10] TXCLR ro — TX FIFO Clear Status
    values as SPGSS2_UC3_I2CC_IPSPECIFIC_SR.TXCLR
  [9] RXCLR ro — RX FIFO Clear Status
    values as SPGSS2_UC3_I2CC_IPSPECIFIC_SR.TXCLR
  [8] STALE_TXFIFO rw
    0=CLEARED (Tx FIFO is not stale); 1=SET (The TX FIFO is stale. This occurs when the TX FIFO was not emptied during the previous I2C transaction.)
  [7] TXMODE rw — FSM is in TX MODE
    0=CLEARED (State Machine is not in TX_DATA, TX_WAIT, TX_ACK or ADDR_ACK state with the bus direction set to read.); 1=SET (State Machine is in TX_DATA, TX_WAIT, TX_ACK or ADDR_ACK state with the bus direction set to read.)
  [6] BUSBSY rw — I2C bus is busy
    0=CLEARED (The I2C Bus is not busy); 1=SET (The I2C Bus is busy. This is cleared on a timeout.)
  [2] RXMODE rw — Target FSM is in Rx MODE
    0=CLEARED (The Target State Machine is not in the RX_DATA, RX_ACK, RX_WAIT, RX_ACK_WAIT or ADDR_ACK state with the bus direction set to write.); 1=SET (The Target State Machine is in the RX_DATA, RX_ACK, RX_WAIT, RX_ACK_WAIT or ADDR_ACK state with the bus direction set to write.)
  [1] TREQ ro — Transmit Request
    0=CLEARED (No outstanding transmit request.); 1=SET (I2C Target is addressed as a transmitter and is using clock stretching to delay the Controller until data has been written to the TXDATA FIFO (TX FIFO is empty).)
  [0] RREQ ro — Receive Request
    0=CLEARED (No outstanding receive data.); 1=SET (Module has outstanding receive data and is using clock stretching to delay the Controller until the data has been read from the RXDATA FIFO (RX FIFO is full).)
{0x4110C+0x2000*i} SPGSS2_UC{i}_I2CT_IPSPECIFIC_IFLS (i=0..3) — Interrupt FIFO Level Select Register
  [7] RXCLR — RX FIFO CLEAR. Setting this bit will clear the RX FIFO contents.
    0=DISABLE (Disable FIFO clear); 1=ENABLE (Enable FIFO Clear)
  [6:4] RXIFLSEL — FIFO Level Select for generating events (interrupt/dma). Note: for undefined settings the default configuration is used.
    1=LVL_1_4 (RX FIFO >= 1/4 full); 2=LVL_1_2 (RX FIFO >= 1/2 full (default)); 3=LVL_3_4 (RX FIFO >= 3/4 full); 4=LVL_NOT_EMPTY (Opposite of empty); 5=LVL_FULL (RX FIFO is full); 6=LVL_ALMOST_FULL (RX_FIFO >= (MAX_FIFO_LEN -1)); 7=LVL_ALMOST_EMPTY (RX_FIFO <= 1)
  [3] TXCLR — TX FIFO CLEAR. Setting this bit will clear the TX FIFO contents.
    0=DISABLE (Disable FIFO clear); 1=ENABLE (Enable FIFO Clear)
  [2:0] TXIFLSEL — FIFO Level Select for generating events (interrupt/dma). Note: for undefined settings the default configuration is used.
    1=LVL_3_4 (TX FIFO <= 3/4 empty); 2=LVL_1_2 (TX FIFO <= 1/2 empty (default)); 3=LVL_1_4 (TX FIFO <= 1/4 empty); 4=LVL_NOT_FULL (Opposite of full); 5=LVL_EMPTY (TX FIFO is empty); 6=LVL_ALMOST_EMPTY (TX FIFO <= 1); 7=LVL_ALMOST_FULL (TX_FIFO >= (MAX_FIFO_LEN -1))
{0x41118+0x2000*i} SPGSS2_UC{i}_I2CT_IPSPECIFIC_GFCTL (i=0..2) — I2C Glitch Filter Control
  [2:0] DGFSEL — Glitch Suppression Pulse Width This field controls the pulse width select for glitch suppression on the SCL and SDA lines. The following values are the glitch suppression values in terms of functional clocks. (Core Domain only)
    0=DISABLED (Bypass); 1=CLK_1 (1 clock); 2=CLK_2 (2 clocks); 3=CLK_3 (3 clocks); 4=CLK_4 (4 clocks); 5=CLK_8 (8 clocks); 6=CLK_16 (16 clocks); 7=CLK_31 (31 clocks)
{0x41120+0x2000*i} SPGSS2_UC{i}_I2CT_IPSPECIFIC_TTXDATA (i=0..3) — I2C TXData
  [7:0] DATA — Transmit Data This byte contains the data to be transferred during the next transaction.
    0=MINIMUM (Smallest value); 255=MAXIMUM (Highest possible value)
{0x41124+0x2000*i} SPGSS2_UC{i}_I2CT_IPSPECIFIC_RXDATA ro (i=0..3) — I2C RXData
  [7:0] DATA — Received Data. This field contains the last received data.
    values as SPGSS2_UC0_I2CT_IPSPECIFIC_TTXDATA.DATA
{0x4114C+0x2000*i} SPGSS2_UC{i}_I2CT_IPSPECIFIC_OAR (i=0..3) — I2C Own Address
  [15] MODE — This bit selects the adressing mode to be used. When 0, 7-bit addressing is used. When 1, 10-bit addressing is used.
    0=Enable 7-bit addressing; 1=Enable 10-bit addressing
  [14] OAREN — Own Address Enable
    0=DISABLE (Disable OAR address); 1=ENABLE (Enable OAR address)
  [9:0] OAR — Own Address: This field specifies bits A9 through A0 of the Target address. In 7-bit addressing mode as selected by I2CSOAR.MODE bit, the top 3 bits are don't care
    0=MINIMUM (Smallest value); 0x3FF=MAXIMUM (Highest possible value)
{0x41150+0x2000*i} SPGSS2_UC{i}_I2CT_IPSPECIFIC_TIMEOUT_CNT ro (i=0..2) — I2C Timeout Count Register
  [7:0] TCNTA — Timeout Count A Current Count: This field contains the upper 8 bits of a 12-bit current counter for timeout counter A
    values as SPGSS2_UC3_I2CC_IPSPECIFIC_TIMEOUT_CNT.TCNTB
{0x41154+0x2000*i} SPGSS2_UC{i}_I2CT_IPSPECIFIC_TIMEOUT_CTL (i=0..2) — I2C Timeout Count Control Register
  [15] TCNTAEN — Timeout Counter A Enable
    values as SPGSS2_UC3_I2CC_IPSPECIFIC_TIMEOUT_CTL.TCNTBEN
  [7:0] TCNTLA — Timeout counter A load value Counter A is used for SCL low detection. This field contains the upper 8 bits of a 12-bit pre-load value for the Timeout A count. NOTE: The value of CNTLA must be greater than 1h. Each count is equal to 520 times the timeout period of functional clock. For example, with 8MHz functional clock and a 100KHz operating I2C clock, one timeout period will be equal to (1 / 8MHz) * 520 or 65 us.
    values as SPGSS2_UC3_I2CC_IPSPECIFIC_TIMEOUT_CNT.TCNTB
{0x41E00+0x2000*i} SPGSS2_UC{i}_I2CT_LMGMT_DFT_ATRT_TEST0 (i=0..3) — Test 0 register
  [4:0] DTB_MUX_SEL — This bit field is used to select DTB mux digital output signals.
    0=DISABLE (Disables DTB MUX); {v}=GRP{v} (Selects test group {v}) (v=1..7)
